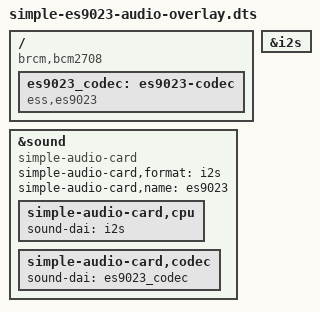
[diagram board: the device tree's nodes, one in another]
// Definitions for a generic board or HAT using ESS Sabre ES9023 DAC
/dts-v1/;
/plugin/;

/ {
	compatible = "brcm,bcm2708";

	fragment@0 {
		target = <&i2s>;
		__overlay__ {
			status = "okay";
		};
	};

	fragment@1 {
		target-path = "/";
		__overlay__ {
			es9023_codec: es9023-codec {
				#sound-dai-cells = <0>;
				compatible = "ess,es9023";
				status = "okay";
			};
		};
	};

	fragment@2 {
		target = <&sound>;
		simple_audio_card: __overlay__ {
			compatible = "simple-audio-card";
			simple-audio-card,format = "i2s";
			simple-audio-card,name = "es9023";
			status = "okay";
			simple-audio-card,cpu {
				sound-dai = <&i2s>;
			};
			simple-audio-card,codec {
				sound-dai = <&es9023_codec>;
			};
		};
	};

	__overrides__ {
		384k = <&es9023_codec>,"es9023,384k?";
		card_name = <&simple_audio_card>,"simple-audio-card,name";
	};
};
